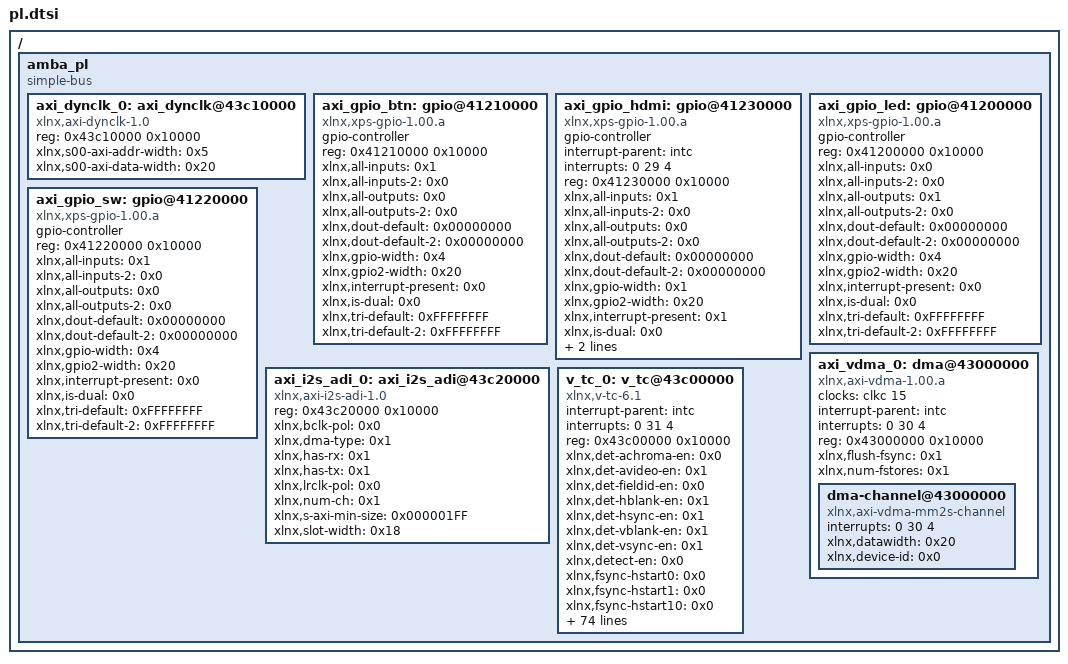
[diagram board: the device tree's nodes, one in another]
/*
 * CAUTION: This file is automatically generated by Xilinx.
 * Version: HSI 2015.4
 * Today is: Fri Mar  4 15:40:49 2016
*/


/ {
	amba_pl: amba_pl {
		#address-cells = <1>;
		#size-cells = <1>;
		compatible = "simple-bus";
		ranges ;
		axi_dynclk_0: axi_dynclk@43c10000 {
			compatible = "xlnx,axi-dynclk-1.0";
			reg = <0x43c10000 0x10000>;
			xlnx,s00-axi-addr-width = <0x5>;
			xlnx,s00-axi-data-width = <0x20>;
		};
		axi_gpio_btn: gpio@41210000 {
			#gpio-cells = <2>;
			compatible = "xlnx,xps-gpio-1.00.a";
			gpio-controller ;
			reg = <0x41210000 0x10000>;
			xlnx,all-inputs = <0x1>;
			xlnx,all-inputs-2 = <0x0>;
			xlnx,all-outputs = <0x0>;
			xlnx,all-outputs-2 = <0x0>;
			xlnx,dout-default = <0x00000000>;
			xlnx,dout-default-2 = <0x00000000>;
			xlnx,gpio-width = <0x4>;
			xlnx,gpio2-width = <0x20>;
			xlnx,interrupt-present = <0x0>;
			xlnx,is-dual = <0x0>;
			xlnx,tri-default = <0xFFFFFFFF>;
			xlnx,tri-default-2 = <0xFFFFFFFF>;
		};
		axi_gpio_hdmi: gpio@41230000 {
			#gpio-cells = <2>;
			compatible = "xlnx,xps-gpio-1.00.a";
			gpio-controller ;
			interrupt-parent = <&intc>;
			interrupts = <0 29 4>;
			reg = <0x41230000 0x10000>;
			xlnx,all-inputs = <0x1>;
			xlnx,all-inputs-2 = <0x0>;
			xlnx,all-outputs = <0x0>;
			xlnx,all-outputs-2 = <0x0>;
			xlnx,dout-default = <0x00000000>;
			xlnx,dout-default-2 = <0x00000000>;
			xlnx,gpio-width = <0x1>;
			xlnx,gpio2-width = <0x20>;
			xlnx,interrupt-present = <0x1>;
			xlnx,is-dual = <0x0>;
			xlnx,tri-default = <0xFFFFFFFF>;
			xlnx,tri-default-2 = <0xFFFFFFFF>;
		};
		axi_gpio_led: gpio@41200000 {
			#gpio-cells = <2>;
			compatible = "xlnx,xps-gpio-1.00.a";
			gpio-controller ;
			reg = <0x41200000 0x10000>;
			xlnx,all-inputs = <0x0>;
			xlnx,all-inputs-2 = <0x0>;
			xlnx,all-outputs = <0x1>;
			xlnx,all-outputs-2 = <0x0>;
			xlnx,dout-default = <0x00000000>;
			xlnx,dout-default-2 = <0x00000000>;
			xlnx,gpio-width = <0x4>;
			xlnx,gpio2-width = <0x20>;
			xlnx,interrupt-present = <0x0>;
			xlnx,is-dual = <0x0>;
			xlnx,tri-default = <0xFFFFFFFF>;
			xlnx,tri-default-2 = <0xFFFFFFFF>;
		};
		axi_gpio_sw: gpio@41220000 {
			#gpio-cells = <2>;
			compatible = "xlnx,xps-gpio-1.00.a";
			gpio-controller ;
			reg = <0x41220000 0x10000>;
			xlnx,all-inputs = <0x1>;
			xlnx,all-inputs-2 = <0x0>;
			xlnx,all-outputs = <0x0>;
			xlnx,all-outputs-2 = <0x0>;
			xlnx,dout-default = <0x00000000>;
			xlnx,dout-default-2 = <0x00000000>;
			xlnx,gpio-width = <0x4>;
			xlnx,gpio2-width = <0x20>;
			xlnx,interrupt-present = <0x0>;
			xlnx,is-dual = <0x0>;
			xlnx,tri-default = <0xFFFFFFFF>;
			xlnx,tri-default-2 = <0xFFFFFFFF>;
		};
		axi_i2s_adi_0: axi_i2s_adi@43c20000 {
			compatible = "xlnx,axi-i2s-adi-1.0";
			reg = <0x43c20000 0x10000>;
			xlnx,bclk-pol = <0x0>;
			xlnx,dma-type = <0x1>;
			xlnx,has-rx = <0x1>;
			xlnx,has-tx = <0x1>;
			xlnx,lrclk-pol = <0x0>;
			xlnx,num-ch = <0x1>;
			xlnx,s-axi-min-size = <0x000001FF>;
			xlnx,slot-width = <0x18>;
		};
		axi_vdma_0: dma@43000000 {
			#dma-cells = <1>;
			compatible = "xlnx,axi-vdma-1.00.a";
			clocks = <&clkc 15>;
			clock-names = "s_axi_lite_aclk";
			interrupt-parent = <&intc>;
			interrupts = <0 30 4>;
			reg = <0x43000000 0x10000>;
			xlnx,flush-fsync = <0x1>;
			xlnx,num-fstores = <0x1>;
			dma-channel@43000000 {
				compatible = "xlnx,axi-vdma-mm2s-channel";
				interrupts = <0 30 4>;
				xlnx,datawidth = <0x20>;
				xlnx,device-id = <0x0>;
			};
		};
		v_tc_0: v_tc@43c00000 {
			compatible = "xlnx,v-tc-6.1";
			interrupt-parent = <&intc>;
			interrupts = <0 31 4>;
			reg = <0x43c00000 0x10000>;
			xlnx,det-achroma-en = <0x0>;
			xlnx,det-avideo-en = <0x1>;
			xlnx,det-fieldid-en = <0x0>;
			xlnx,det-hblank-en = <0x1>;
			xlnx,det-hsync-en = <0x1>;
			xlnx,det-vblank-en = <0x1>;
			xlnx,det-vsync-en = <0x1>;
			xlnx,detect-en = <0x0>;
			xlnx,fsync-hstart0 = <0x0>;
			xlnx,fsync-hstart1 = <0x0>;
			xlnx,fsync-hstart10 = <0x0>;
			xlnx,fsync-hstart11 = <0x0>;
			xlnx,fsync-hstart12 = <0x0>;
			xlnx,fsync-hstart13 = <0x0>;
			xlnx,fsync-hstart14 = <0x0>;
			xlnx,fsync-hstart15 = <0x0>;
			xlnx,fsync-hstart2 = <0x0>;
			xlnx,fsync-hstart3 = <0x0>;
			xlnx,fsync-hstart4 = <0x0>;
			xlnx,fsync-hstart5 = <0x0>;
			xlnx,fsync-hstart6 = <0x0>;
			xlnx,fsync-hstart7 = <0x0>;
			xlnx,fsync-hstart8 = <0x0>;
			xlnx,fsync-hstart9 = <0x0>;
			xlnx,fsync-vstart0 = <0x0>;
			xlnx,fsync-vstart1 = <0x0>;
			xlnx,fsync-vstart10 = <0x0>;
			xlnx,fsync-vstart11 = <0x0>;
			xlnx,fsync-vstart12 = <0x0>;
			xlnx,fsync-vstart13 = <0x0>;
			xlnx,fsync-vstart14 = <0x0>;
			xlnx,fsync-vstart15 = <0x0>;
			xlnx,fsync-vstart2 = <0x0>;
			xlnx,fsync-vstart3 = <0x0>;
			xlnx,fsync-vstart4 = <0x0>;
			xlnx,fsync-vstart5 = <0x0>;
			xlnx,fsync-vstart6 = <0x0>;
			xlnx,fsync-vstart7 = <0x0>;
			xlnx,fsync-vstart8 = <0x0>;
			xlnx,fsync-vstart9 = <0x0>;
			xlnx,gen-achroma-en = <0x0>;
			xlnx,gen-achroma-polarity = <0x1>;
			xlnx,gen-auto-switch = <0x0>;
			xlnx,gen-avideo-en = <0x1>;
			xlnx,gen-avideo-polarity = <0x1>;
			xlnx,gen-cparity = <0x0>;
			xlnx,gen-f0-vblank-hend = <0x500>;
			xlnx,gen-f0-vblank-hstart = <0x500>;
			xlnx,gen-f0-vframe-size = <0x2ee>;
			xlnx,gen-f0-vsync-hend = <0x500>;
			xlnx,gen-f0-vsync-hstart = <0x500>;
			xlnx,gen-f0-vsync-vend = <0x2d9>;
			xlnx,gen-f0-vsync-vstart = <0x2d4>;
			xlnx,gen-f1-vblank-hend = <0x500>;
			xlnx,gen-f1-vblank-hstart = <0x500>;
			xlnx,gen-f1-vframe-size = <0x2ee>;
			xlnx,gen-f1-vsync-hend = <0x500>;
			xlnx,gen-f1-vsync-hstart = <0x500>;
			xlnx,gen-f1-vsync-vend = <0x2d9>;
			xlnx,gen-f1-vsync-vstart = <0x2d4>;
			xlnx,gen-fieldid-en = <0x0>;
			xlnx,gen-fieldid-polarity = <0x1>;
			xlnx,gen-hactive-size = <0x500>;
			xlnx,gen-hblank-en = <0x1>;
			xlnx,gen-hblank-polarity = <0x1>;
			xlnx,gen-hframe-size = <0x672>;
			xlnx,gen-hsync-en = <0x1>;
			xlnx,gen-hsync-end = <0x596>;
			xlnx,gen-hsync-polarity = <0x1>;
			xlnx,gen-hsync-start = <0x56e>;
			xlnx,gen-interlaced = <0x0>;
			xlnx,gen-vactive-size = <0x2d0>;
			xlnx,gen-vblank-en = <0x1>;
			xlnx,gen-vblank-polarity = <0x1>;
			xlnx,gen-video-format = <0x2>;
			xlnx,gen-vsync-en = <0x1>;
			xlnx,gen-vsync-polarity = <0x1>;
			xlnx,generate-en = <0x1>;
			xlnx,has-axi4-lite = <0x1>;
			xlnx,has-intc-if = <0x0>;
			xlnx,interlace-en = <0x0>;
			xlnx,max-lines = <0x1000>;
			xlnx,max-pixels = <0x1000>;
			xlnx,num-fsyncs = <0x1>;
			xlnx,sync-en = <0x0>;
		};
	};
};
